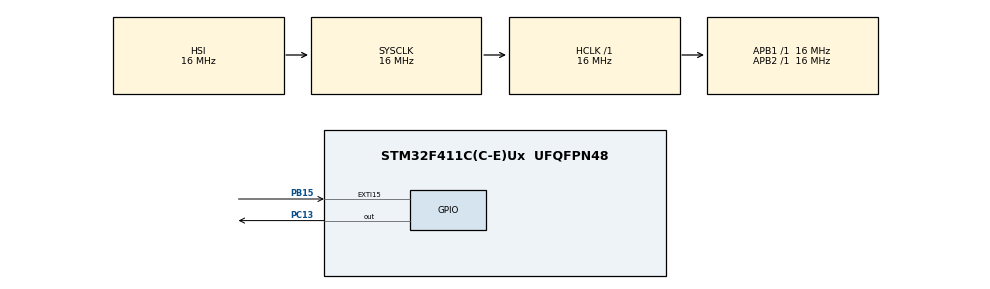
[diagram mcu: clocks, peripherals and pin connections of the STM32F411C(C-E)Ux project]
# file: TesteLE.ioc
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Mcu.Family=STM32F4
Mcu.Name=STM32F411C(C-E)Ux
Mcu.Package=UFQFPN48
NVIC.EXTI15_10_IRQn=true\:0\:0\:false\:false\:true\:true\:true\:true
NVIC.PriorityGroup=NVIC_PRIORITYGROUP_4
PA13.Mode=Serial_Wire
PA13.Signal=SYS_JTMS-SWDIO
PA14.Mode=Serial_Wire
PA14.Signal=SYS_JTCK-SWCLK
PB15.GPIO_PuPd=GPIO_PULLUP
PB15.Signal=GPXTI15
PC13-ANTI_TAMP.Signal=GPIO_Output
ProjectManager.HeapSize=0x200
ProjectManager.StackSize=0x400
ProjectManager.TargetToolchain=STM32CubeIDE
RCC.AHBFreq_Value=16000000
RCC.APB1Freq_Value=16000000
RCC.APB2Freq_Value=16000000
RCC.CortexFreq_Value=16000000
RCC.HSE_VALUE=25000000
RCC.HSI_VALUE=16000000
RCC.SYSCLKFreq_VALUE=16000000
RCC.VCOOutputFreq_Value=192000000
board=custom

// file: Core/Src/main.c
/* USER CODE BEGIN Header */
/**
  ******************************************************************************
  * @file           : main.c
  * @brief          : Main program body
  ******************************************************************************
  * @attention
  *
  * Copyright (c) 2023 STMicroelectronics.
  * All rights reserved.
  *
  * This software is licensed under terms that can be found in the LICENSE file
  * in the root directory of this software component.
  * If no LICENSE file comes with this software, it is provided AS-IS.
  *
  ******************************************************************************
  */
/* USER CODE END Header */
#include "main.h"

void SystemClock_Config(void);
static void MX_GPIO_Init(void);

/* USER CODE BEGIN 0 */

int _write(int32_t file, uint8_t *ptr, int32_t len)
{
	for (int i = 0; i < len; i++ )
	{
		ITM_SendChar(*ptr++);
	}
	return len;
}

uint8_t flag = 0;

void HAL_GPIO_EXTI_Callback(uint16_t GPIO_Pin)
{
	if(GPIO_Pin == GPIO_PIN_15) // If The INT Source Is EXTI Line9 (A9 Pin)
	{
		flag ++;
	}
}

/* USER CODE END 0 */

int main(void)
{

  /* MCU Configuration--------------------------------------------------------*/

  /* Reset of all peripherals, Initializes the Flash interface and the Systick. */
  HAL_Init();

  /* Configure the system clock */
  SystemClock_Config();

  /* Initialize all configured peripherals */
  MX_GPIO_Init();

  /* Infinite loop */
  /* USER CODE BEGIN WHILE */
  //GPIO_PinState status;

  while (1)
  {
    /* USER CODE END WHILE */

    /* USER CODE BEGIN 3 */

	  HAL_Delay(1000);
	  HAL_GPIO_WritePin(GPIOC, GPIO_PIN_13, 1);
	  HAL_SuspendTick();
	  HAL_PWR_EnterSLEEPMode(PWR_MAINREGULATOR_ON,PWR_SLEEPENTRY_WFI);
	  HAL_ResumeTick();
	  HAL_GPIO_WritePin(GPIOC, GPIO_PIN_13, 0);

  }

  /* USER CODE END 3 */
}

void SystemClock_Config(void)
{
  RCC_OscInitTypeDef RCC_OscInitStruct = {0};
  RCC_ClkInitTypeDef RCC_ClkInitStruct = {0};

  /** Configure the main internal regulator output voltage
  */
  __HAL_RCC_PWR_CLK_ENABLE();
  __HAL_PWR_VOLTAGESCALING_CONFIG(PWR_REGULATOR_VOLTAGE_SCALE1);

  /** Initializes the RCC Oscillators according to the specified parameters
  * in the RCC_OscInitTypeDef structure.
  */
  RCC_OscInitStruct.OscillatorType = RCC_OSCILLATORTYPE_HSI;
  RCC_OscInitStruct.HSIState = RCC_HSI_ON;
  RCC_OscInitStruct.HSICalibrationValue = RCC_HSICALIBRATION_DEFAULT;
  RCC_OscInitStruct.PLL.PLLState = RCC_PLL_NONE;
  if (HAL_RCC_OscConfig(&RCC_OscInitStruct) != HAL_OK)
  {
    Error_Handler();
  }

  /** Initializes the CPU, AHB and APB buses clocks
  */
  RCC_ClkInitStruct.ClockType = RCC_CLOCKTYPE_HCLK|RCC_CLOCKTYPE_SYSCLK
                              |RCC_CLOCKTYPE_PCLK1|RCC_CLOCKTYPE_PCLK2;
  RCC_ClkInitStruct.SYSCLKSource = RCC_SYSCLKSOURCE_HSI;
  RCC_ClkInitStruct.AHBCLKDivider = RCC_SYSCLK_DIV1;
  RCC_ClkInitStruct.APB1CLKDivider = RCC_HCLK_DIV1;
  RCC_ClkInitStruct.APB2CLKDivider = RCC_HCLK_DIV1;

  if (HAL_RCC_ClockConfig(&RCC_ClkInitStruct, FLASH_LATENCY_0) != HAL_OK)
  {
    Error_Handler();
  }
}

static void MX_GPIO_Init(void)
{
  GPIO_InitTypeDef GPIO_InitStruct = {0};

  /* GPIO Ports Clock Enable */
  __HAL_RCC_GPIOC_CLK_ENABLE();
  __HAL_RCC_GPIOH_CLK_ENABLE();
  __HAL_RCC_GPIOA_CLK_ENABLE();
  __HAL_RCC_GPIOB_CLK_ENABLE();

  /*Configure GPIO pin Output Level */
  HAL_GPIO_WritePin(GPIOC, GPIO_PIN_13, GPIO_PIN_RESET);

  /*Configure GPIO pin : PC13 */
  GPIO_InitStruct.Pin = GPIO_PIN_13;
  GPIO_InitStruct.Mode = GPIO_MODE_OUTPUT_PP;
  GPIO_InitStruct.Pull = GPIO_NOPULL;
  GPIO_InitStruct.Speed = GPIO_SPEED_FREQ_LOW;
  HAL_GPIO_Init(GPIOC, &GPIO_InitStruct);

  /*Configure GPIO pins : PC14 PC15 */
  GPIO_InitStruct.Pin = GPIO_PIN_14|GPIO_PIN_15;
  GPIO_InitStruct.Mode = GPIO_MODE_ANALOG;
  GPIO_InitStruct.Pull = GPIO_NOPULL;
  HAL_GPIO_Init(GPIOC, &GPIO_InitStruct);

  /*Configure GPIO pins : PH0 PH1 */
  GPIO_InitStruct.Pin = GPIO_PIN_0|GPIO_PIN_1;
  GPIO_InitStruct.Mode = GPIO_MODE_ANALOG;
  GPIO_InitStruct.Pull = GPIO_NOPULL;
  HAL_GPIO_Init(GPIOH, &GPIO_InitStruct);

  /*Configure GPIO pins : PA0 PA1 PA2 PA3
                           PA4 PA5 PA6 PA7
                           PA8 PA9 PA10 PA11
                           PA12 PA15 */
  GPIO_InitStruct.Pin = GPIO_PIN_0|GPIO_PIN_1|GPIO_PIN_2|GPIO_PIN_3
                          |GPIO_PIN_4|GPIO_PIN_5|GPIO_PIN_6|GPIO_PIN_7
                          |GPIO_PIN_8|GPIO_PIN_9|GPIO_PIN_10|GPIO_PIN_11
                          |GPIO_PIN_12|GPIO_PIN_15;
  GPIO_InitStruct.Mode = GPIO_MODE_ANALOG;
  GPIO_InitStruct.Pull = GPIO_NOPULL;
  HAL_GPIO_Init(GPIOA, &GPIO_InitStruct);

  /*Configure GPIO pins : PB0 PB1 PB2 PB10
                           PB12 PB13 PB14 PB3
                           PB4 PB5 PB6 PB7
                           PB8 PB9 */
  GPIO_InitStruct.Pin = GPIO_PIN_0|GPIO_PIN_1|GPIO_PIN_2|GPIO_PIN_10
                          |GPIO_PIN_12|GPIO_PIN_13|GPIO_PIN_14|GPIO_PIN_3
                          |GPIO_PIN_4|GPIO_PIN_5|GPIO_PIN_6|GPIO_PIN_7
                          |GPIO_PIN_8|GPIO_PIN_9;
  GPIO_InitStruct.Mode = GPIO_MODE_ANALOG;
  GPIO_InitStruct.Pull = GPIO_NOPULL;
  HAL_GPIO_Init(GPIOB, &GPIO_InitStruct);

  /*Configure GPIO pin : PB15 */
  GPIO_InitStruct.Pin = GPIO_PIN_15;
  GPIO_InitStruct.Mode = GPIO_MODE_IT_RISING;
  GPIO_InitStruct.Pull = GPIO_PULLUP;
  HAL_GPIO_Init(GPIOB, &GPIO_InitStruct);

  /* EXTI interrupt init*/
  HAL_NVIC_SetPriority(EXTI15_10_IRQn, 0, 0);
  HAL_NVIC_EnableIRQ(EXTI15_10_IRQn);

}

void Error_Handler(void)
{
  __disable_irq();
  while (1)
  {
  }
}
